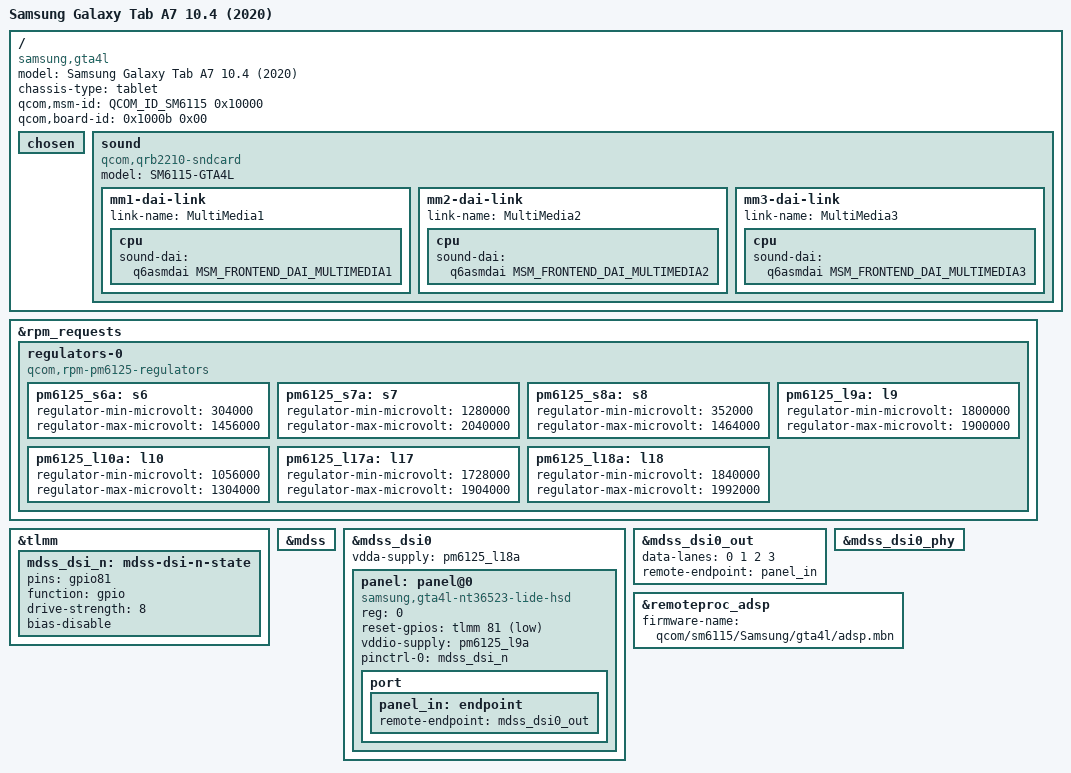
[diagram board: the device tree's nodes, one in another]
// SPDX-License-Identifier: (GPL-2.0+ OR BSD-3-Clause)
/*
 * Samsung Galaxy Tab A7 10.4 (2020) (SM-T500) mainline device tree
 * Panel: Novatek NT36523 lide-hsd (single-DSI, 1200x2000)
 */

/dts-v1/;

#include "sm6115.dtsi"
#include "pm6125.dtsi"
#include <dt-bindings/arm/qcom,ids.h>
#include <dt-bindings/sound/qcom,q6asm.h>

/ {
	model = "Samsung Galaxy Tab A7 10.4 (2020)";
	compatible = "samsung,gta4l", "qcom,sm6115";
	chassis-type = "tablet";

	qcom,msm-id = <QCOM_ID_SM6115 0x10000>;
	qcom,board-id = <0x1000b 0x00>;

	chosen {
		#address-cells = <2>;
		#size-cells = <2>;
		ranges;
	};

	/*
	 * ADSP-only sound card. SoC q6afe/q6asm/q6adm plumbing is in
	 * sm6115.dtsi. The WCD9375 codec path (bolero + rx/tx/va macros +
	 * SoundWire) is NOT yet ported to mainline sm6115; the MM frontends
	 * below use a dummy codec and expose the ADSP PCM endpoints so the
	 * card registers and DSP capture/playback (e.g. via the ADSP) can be
	 * used. Speaker/headset over the codec is a known gap (see report).
	 * ponytail: card exposes only MM DAIs; add bolero/swr/wcd9375 backend
	 * links when the macro/codec nodes are ported to sm6115.dtsi.
	 */
	sound {
		compatible = "qcom,qrb2210-sndcard";
		model = "SM6115-GTA4L";

		mm1-dai-link {
			link-name = "MultiMedia1";

			cpu {
				sound-dai = <&q6asmdai MSM_FRONTEND_DAI_MULTIMEDIA1>;
			};
		};

		mm2-dai-link {
			link-name = "MultiMedia2";

			cpu {
				sound-dai = <&q6asmdai MSM_FRONTEND_DAI_MULTIMEDIA2>;
			};
		};

		mm3-dai-link {
			link-name = "MultiMedia3";

			cpu {
				sound-dai = <&q6asmdai MSM_FRONTEND_DAI_MULTIMEDIA3>;
			};
		};
	};
};

&rpm_requests {
	regulators-0 {
		compatible = "qcom,rpm-pm6125-regulators";

		pm6125_s6a: s6 {
			regulator-min-microvolt = <304000>;
			regulator-max-microvolt = <1456000>;
		};

		pm6125_s7a: s7 {
			regulator-min-microvolt = <1280000>;
			regulator-max-microvolt = <2040000>;
		};

		pm6125_s8a: s8 {
			regulator-min-microvolt = <352000>;
			regulator-max-microvolt = <1464000>;
		};

		pm6125_l9a: l9 {
			regulator-min-microvolt = <1800000>;
			regulator-max-microvolt = <1900000>;
		};

		pm6125_l10a: l10 {
			regulator-min-microvolt = <1056000>;
			regulator-max-microvolt = <1304000>;
		};

		pm6125_l17a: l17 {
			regulator-min-microvolt = <1728000>;
			regulator-max-microvolt = <1904000>;
		};

		pm6125_l18a: l18 {
			regulator-min-microvolt = <1840000>;
			regulator-max-microvolt = <1992000>;
		};
	};
};

&tlmm {
	mdss_dsi_n: mdss-dsi-n-state {
		pins = "gpio81";
		function = "gpio";
		drive-strength = <8>;
		bias-disable;
	};
};

&mdss {
	status = "okay";
};

&mdss_dsi0 {
	vdda-supply = <&pm6125_l18a>;
	status = "okay";

	panel: panel@0 {
		compatible = "samsung,gta4l-nt36523-lide-hsd";
		reg = <0>;

		reset-gpios = <&tlmm 81 GPIO_ACTIVE_LOW>;
		vddio-supply = <&pm6125_l9a>;

		pinctrl-0 = <&mdss_dsi_n>;
		pinctrl-names = "default";

		port {
			panel_in: endpoint {
				remote-endpoint = <&mdss_dsi0_out>;
			};
		};
	};
};

&mdss_dsi0_out {
	data-lanes = <0 1 2 3>;
	remote-endpoint = <&panel_in>;
};

&mdss_dsi0_phy {
	status = "okay";
};

&remoteproc_adsp {
	firmware-name = "qcom/sm6115/Samsung/gta4l/adsp.mbn";
	status = "okay";
};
